# AM13E23219 register map
Vendor: Texas Instruments; File version: 1.0
CPU: CM33 r0p1, little endian, MPU, FPU, VTOR, 4 interrupt priority bits
Registers are 32-bit, read-write, reset 0x0 unless marked. A register's access mark holds for its fields unless they carry their own. Offsets are from the block's base; [hi:lo] are bit positions; lines under a group give offsets from that group; {n}, {i} and the like mark numbered series; 'fields as' and 'values as' point back to an identical list.

## MCPWM0 — MCPWM module
Base 0x40010000
Same registers: MCPWM1 0x40011000, MCPWM2 0x40012000
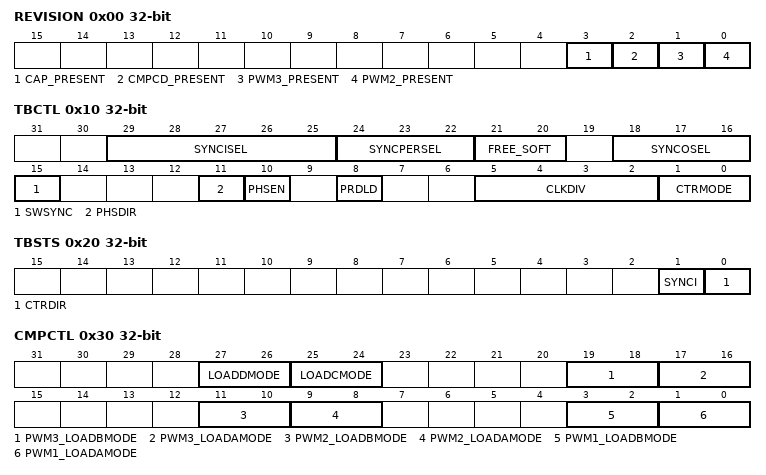
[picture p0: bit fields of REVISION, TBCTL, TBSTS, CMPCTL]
0x00 REVISION ro — IP revision id register
  [3] CAP_PRESENT — Capture mode Present
  [2] CMPCD_PRESENT — Compare C and D Present
  [1] PWM3_PRESENT
  [0] PWM2_PRESENT
0x10 TBCTL — Time base control register
  [29:25] SYNCISEL — Sync Input Select
  [24:22] SYNCPERSEL — Sync peripheral Select
  [21:20] FREE_SOFT — Emulation Mode Bits
  [18:16] SYNCOSEL — Sync Output Select
  [15] SWSYNC — Software Force Sync Pulse
  [11] PHSDIR — Phase Direction Bit
  [10] PHSEN — Phase Load Enable
  [8] PRDLD — Shadow to active load of TBPRD
  [5:2] CLKDIV — Time Base Clock Pre-scaler
  [1:0] CTRMODE — Counter Mode
0x14 TBPRD — Time base period register
  [15:0] TBPRD
0x18 TBPRDS — Time base period shadow register
  [15:0] TBPRDS
0x1C TBPHS — Time base phase offset register
  [15:0] TBPHS — Phase Offset Register
0x20 TBSTS ro — Time base status register
  [1] SYNCI — External Input Sync Status
  [0] CTRDIR — Counter Direction Status
0x24 TBSTSCLR — Time base status clear register
  [1] SYNCI — External Input Sync Status clear
0x28 TBCTR — Time base counter register
  [15:0] TBCTR — Counter Value
0x30 CMPCTL — Counter compare control register
  [27:26] LOADDMODE — Shadow to active load of CMPD
  [25:24] LOADCMODE — Shadow to active load of CMPC
  [19:18] PWM3_LOADBMODE — Shadow to active load of PWM3_CMPB
  [17:16] PWM3_LOADAMODE — Shadow to active load of PWM3_CMPA
  [11:10] PWM2_LOADBMODE — Shadow to active load of PWM2_CMPB
  [9:8] PWM2_LOADAMODE — Shadow to active load of PWM2_CMPA
  [3:2] PWM1_LOADBMODE — Shadow to active load of PWM1_CMPB
  [1:0] PWM1_LOADAMODE — Shadow to active load of PWM1_CMPA
0x40 CMPC — Counter compare C register
  [15:0] CMPC — Compare C register
0x44 CMPD — Counter compare D register
  [15:0] CMPD — Compare D register
0x48 CMPCS — Counter compare C shadow register
  [15:0] CMPCS — Compare C shadow register
0x4C CMPDS — Counter compare D shadow register
  [15:0] CMPDS — Compare D shadow register
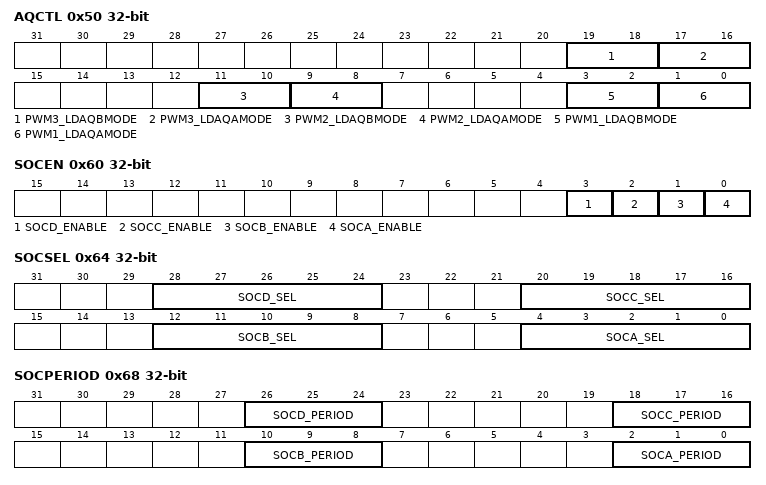
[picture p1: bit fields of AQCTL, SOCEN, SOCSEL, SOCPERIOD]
0x50 AQCTL — Action qualifier control register
  [19:18] PWM3_LDAQBMODE — Shadow to active load of PWM3_AQCTLB
  [17:16] PWM3_LDAQAMODE — Shadow to active load of PWM3_AQCTLA
  [11:10] PWM2_LDAQBMODE — Shadow to active load of PWM2_AQCTLB
  [9:8] PWM2_LDAQAMODE — Shadow to active load of PWM2_AQCTLA
  [3:2] PWM1_LDAQBMODE — Shadow to active load of PWM1_AQCTLB
  [1:0] PWM1_LDAQAMODE — Shadow to active load of PWM1_AQCTLA
0x60 SOCEN — Start of conversion enable
  [3] SOCD_ENABLE — Start of conversion (SOC) D enable
  [2] SOCC_ENABLE — Start of conversion (SOC) C enable
  [1] SOCB_ENABLE — Start of conversion (SOC) B enable
  [0] SOCA_ENABLE — Start of conversion (SOC) A enable
0x64 SOCSEL — Start of conversion selection
  [28:24] SOCD_SEL — Start of conversion (SOC) D select
  [20:16] SOCC_SEL — Start of conversion (SOC) C select
  [12:8] SOCB_SEL — Start of conversion (SOC) B select
  [4:0] SOCA_SEL — Start of conversion (SOC) A select
0x68 SOCPERIOD — Start of conversion period
  [26:24] SOCD_PERIOD — Start of conversion (SOC) D PERIOD
  [18:16] SOCC_PERIOD — Start of conversion (SOC) C PERIOD
  [10:8] SOCB_PERIOD — Start of conversion (SOC) B PERIOD
  [2:0] SOCA_PERIOD — Start of conversion (SOC) A PERIOD
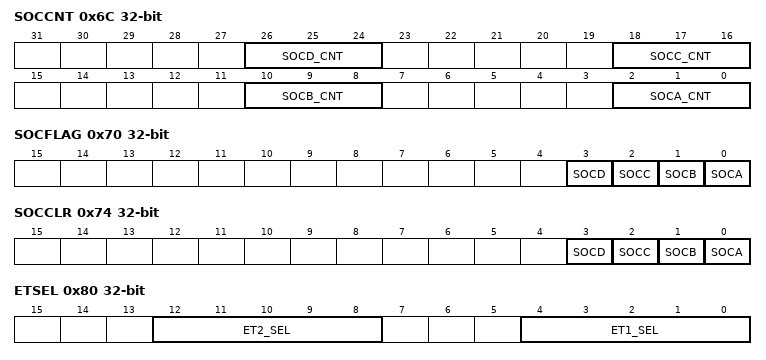
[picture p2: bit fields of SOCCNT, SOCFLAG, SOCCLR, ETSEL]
0x6C SOCCNT ro — Start of conversion count
  [26:24] SOCD_CNT — Start of conversion (SOC) D COUNT
  [18:16] SOCC_CNT — Start of conversion (SOC) C COUNT
  [10:8] SOCB_CNT — Start of conversion (SOC) B COUNT
  [2:0] SOCA_CNT — Start of conversion (SOC) A COUNT
0x70 SOCFLAG ro — Start of conversion flag
  [3] SOCD — SOCD Flag
  [2] SOCC — SOCC Flag
  [1] SOCB — SOCB Flag
  [0] SOCA — SOCA Flag
0x74 SOCCLR — Start of conversion clear
  [3] SOCD — SOCD Clear
  [2] SOCC — SOCC Clear
  [1] SOCB — SOCB Clear
  [0] SOCA — SOCA Clear
0x80 ETSEL — Event trigger selection
  [12:8] ET2_SEL — Event trigger2 selection
  [4:0] ET1_SEL — Event trigger1 selection
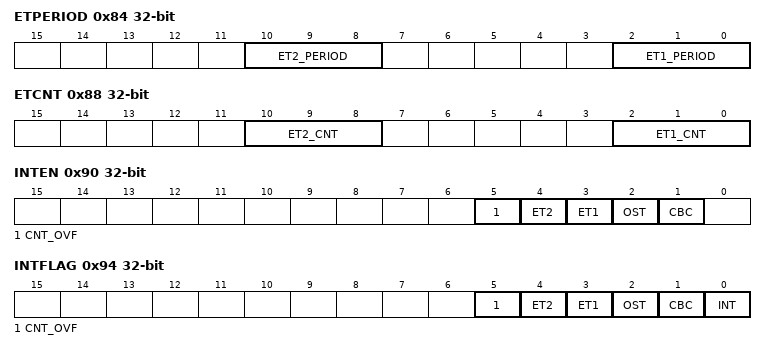
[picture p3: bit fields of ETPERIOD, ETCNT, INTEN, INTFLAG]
0x84 ETPERIOD — Event trigger period
  [10:8] ET2_PERIOD — Event trigger2 PERIOD
  [2:0] ET1_PERIOD — Event trigger1 PERIOD
0x88 ETCNT ro — Event trigger count
  [10:8] ET2_CNT — Event trigger2 COUNT
  [2:0] ET1_CNT — Event trigger1 COUNT
0x90 INTEN — Interrupt enable
  [5] CNT_OVF — Counter overflow interrupt
  [4] ET2 — Enable ET2 interrupt
  [3] ET1 — Enable ET1 interrupt
  [2] OST — Enable OST interrupt
  [1] CBC — Enable CBC interrupt
0x94 INTFLAG ro — Interrupt flag
  [5] CNT_OVF — Counter overflow flag
  [4] ET2 — ET2 interrupt flag
  [3] ET1 — ET1 interrupt flag
  [2] OST — OST interrupt flag
  [1] CBC — CBC interrupt flag
  [0] INT — Global Flag
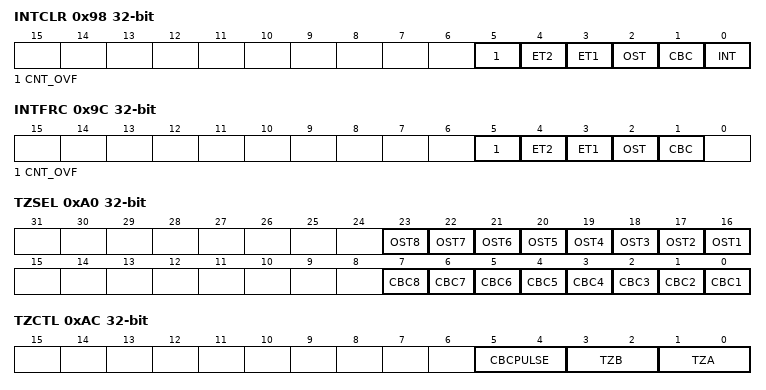
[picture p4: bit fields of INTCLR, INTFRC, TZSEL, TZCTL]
0x98 INTCLR — Interrupt clear
  [5] CNT_OVF — Counter overflow flag
  [4] ET2 — Clear ET2 interrupt flag
  [3] ET1 — Clear ET1 interrupt flag
  [2] OST — Clear OST interrupt flag
  [1] CBC — Clear CBC interrupt flag
  [0] INT — Clear Global Flag
0x9C INTFRC — Interrupt force
  [5] CNT_OVF — Counter overflow flag
  [4] ET2 — Force ET2 interrupt flag
  [3] ET1 — Force ET1 interrupt flag
  [2] OST — Force OST interrupt flag
  [1] CBC — Force CBC interrupt flag
0xA0 TZSEL — Trip Zone selection
  [n+15] OST{n} (n=1..8) — OST TZ{n} select
  [n-1] CBC{n} (n=1..8) — CBC TZ{n} select
0xAC TZCTL — Trip Zone control
  [5:4] CBCPULSE — Clear Pulse for CBC Trip Latch
  [3:2] TZB — TZ1 to TZ8 Trip Action on PWMB
  [1:0] TZA — TZ1 to TZ8 Trip Action on PWMA
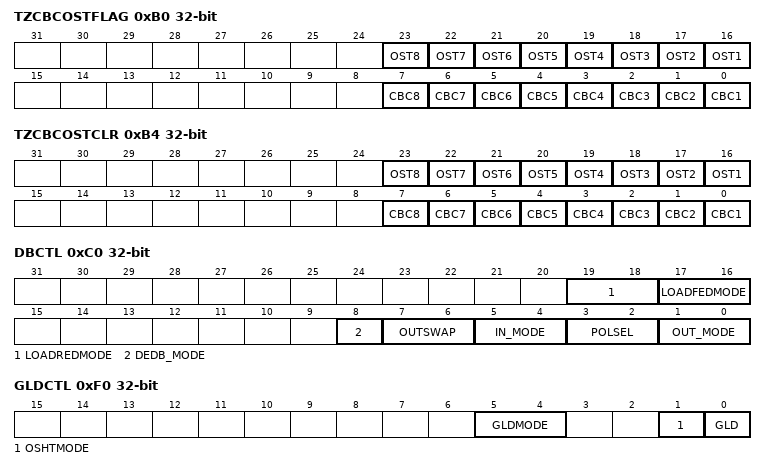
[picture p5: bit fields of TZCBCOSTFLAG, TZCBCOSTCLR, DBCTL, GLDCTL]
0xB0 TZCBCOSTFLAG ro — Trip zone CBCOST flag
  [n+15] OST{n} (n=1..8) — OST TZ{n} Flag
  [7] CBC8 — OST TZ8 Flag
  [n-1] CBC{n} (n=1..7) — CBC TZ{n} Flag
0xB4 TZCBCOSTCLR — Trip zone CBCOST flag clear
  [n+15] OST{n} (n=1..8) — OST TZ{n} Clear
  [7] CBC8 — OST TZ8 Clear
  [n-1] CBC{n} (n=1..7) — CBC TZ{n} Clear
0xC0 DBCTL — Dead band control register
  [19:18] LOADREDMODE — Shadow to active load of DBRED
  [17:16] LOADFEDMODE — Shadow to active load of DBFED
  [8] DEDB_MODE — Dead Band Dual-Edge B Mode Control
  [7:6] OUTSWAP — Dead Band Output Swap Control
  [5:4] IN_MODE — Dead Band Input Select Mode Control
  [3:2] POLSEL — Polarity Select Control
  [1:0] OUT_MODE — Dead Band Output Mode Control
0xD0 DBFED — Dead band fall edge delay
  [13:0] DBFED — Falling edge delay value
0xD4 DBRED — Dead band rise edge delay
  [13:0] DBRED — Rising edge delay value
0xD8 DBFEDS — Dead band fall edge delay shadow register
  [13:0] DBFEDS — Falling edge delay shadow register
0xDC DBREDS — Dead band rise edge delay shadow register
  [13:0] DBREDS — Rising edge delay shadow register
0xF0 GLDCTL — Global load control register
  [5:4] GLDMODE — Select global load event
  [1] OSHTMODE — Global load one-shot enable
  [0] GLD — Global load enable
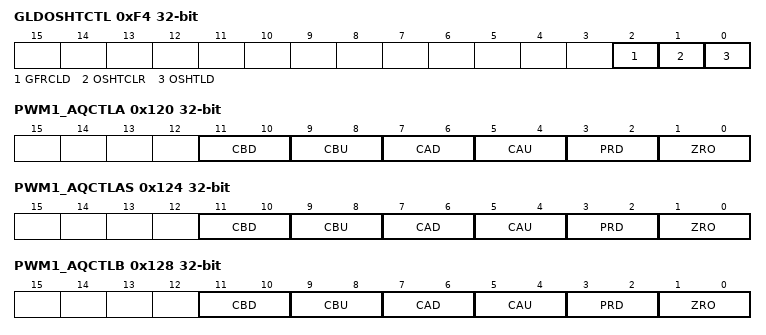
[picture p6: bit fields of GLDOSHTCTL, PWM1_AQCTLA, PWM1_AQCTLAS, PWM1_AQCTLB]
0xF4 GLDOSHTCTL — Global load one shot control register
  [2] GFRCLD — Force load event in one shot mode
  [1] OSHTCLR — Enable Reload Event in One Shot Mode
  [0] OSHTLD — Enable Reload Event in One Shot Mode
0xF8 GLDOSHTSTS ro — Global load one shot status register
  [0] OSHTLATCH — One shot latch output
0x100 PWM1_CMPA — PWM1 counter compare A register
  [15:0] PWM1_CMPA — PWM1 Compare A register
0x104 PWM1_CMPAS — PWM1 counter compare A shadow register
  [15:0] PWM1_CMPAS — PWM1 Compare A shadow register
0x108 PWM1_CMPB — PWM1 counter compare B register
  [15:0] PWM1_CMPB — PWM1 Compare B register
0x10C PWM1_CMPBS — PWM1 counter compare B shadow register
  [15:0] PWM1_CMPBS — PWM1 Compare B shadow register
0x120 PWM1_AQCTLA — PWM1 action qualifier A register
  [11:10] CBD — Action When TBCTR = PWM1_CMPB on Down Count
  [9:8] CBU — Action When TBCTR = PWM1_CMPB on Up Count
  [7:6] CAD — Action When TBCTR = PWM1_CMPA on Down Count
  [5:4] CAU — Action When TBCTR = PWM1_CMPA on Up Count
  [3:2] PRD — Action When TBCTR = TBPRD
  [1:0] ZRO — Action When TBCTR = 0
0x124 PWM1_AQCTLAS — PWM1 action qualifier A shadow register
  fields as PWM1_AQCTLA
0x128 PWM1_AQCTLB — PWM1 action qualifier B register
  fields as PWM1_AQCTLA
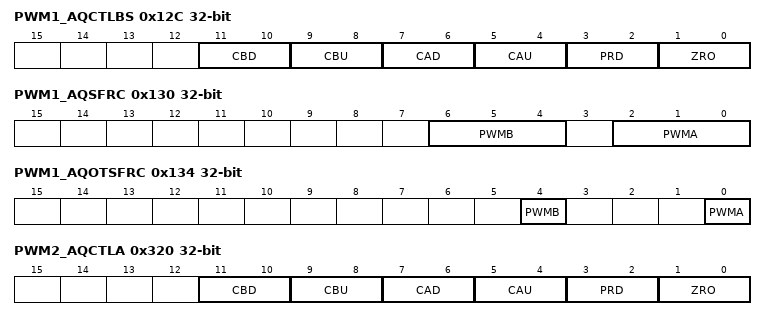
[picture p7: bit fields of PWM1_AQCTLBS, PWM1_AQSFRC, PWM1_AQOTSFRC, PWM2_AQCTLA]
0x12C PWM1_AQCTLBS — PWM1 action qualifier B shadow register
  fields as PWM1_AQCTLA
0x130 PWM1_AQSFRC — PWM1 action qualifier software force
  [6:4] PWMB — Action qualifier software force on PWMB
  [2:0] PWMA — Action qualifier software force on PWMA
0x134 PWM1_AQOTSFRC — PWM1 action qualifier one time software force
  [4] PWMB — Action qualifier software force on PWMB
  [0] PWMA — Action qualifier one time software force on PWMA
0x300 PWM2_CMPA — PWM2 counter compare A register
  [15:0] PWM2_CMPA — PWM2 Compare A register
0x304 PWM2_CMPAS — PWM2 counter compare A shadow register
  [15:0] PWM2_CMPAS — PWM2 Compare A shadow register
0x308 PWM2_CMPB — PWM2 counter compare B register
  [15:0] PWM2_CMPB — PWM2 Compare B register
0x30C PWM2_CMPBS — PWM2 counter compare B shadow register
  [15:0] PWM2_CMPBS — PWM2 Compare B shadow register
0x320 PWM2_AQCTLA — PWM2 action qualifier A register
  [11:10] CBD — Action When TBCTR = PWM2_CMPB on Down Count
  [9:8] CBU — Action When TBCTR = PWM2_CMPB on Up Count
  [7:6] CAD — Action When TBCTR = PWM2_CMPA on Down Count
  [5:4] CAU — Action When TBCTR = PWM2_CMPA on Up Count
  [3:2] PRD — Action When TBCTR = TBPRD
  [1:0] ZRO — Action When TBCTR = 0
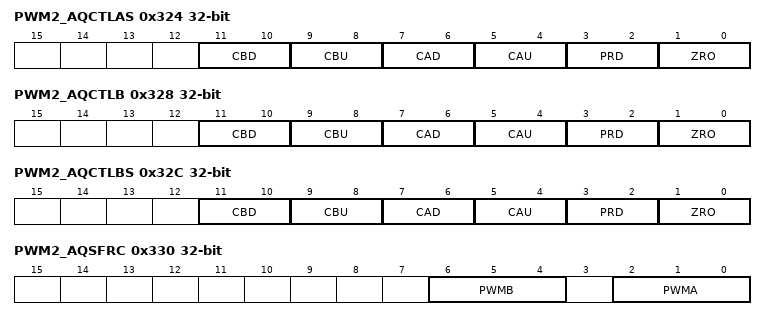
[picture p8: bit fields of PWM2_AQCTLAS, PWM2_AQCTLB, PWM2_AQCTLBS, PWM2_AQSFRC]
0x324 PWM2_AQCTLAS — PWM2 action qualifier A shadow register
  fields as PWM2_AQCTLA
0x328 PWM2_AQCTLB — PWM2 action qualifier B register
  fields as PWM2_AQCTLA
0x32C PWM2_AQCTLBS — PWM2 action qualifier B shadow register
  fields as PWM2_AQCTLA
0x330 PWM2_AQSFRC — PWM2 action qualifier software force
  fields as PWM1_AQSFRC
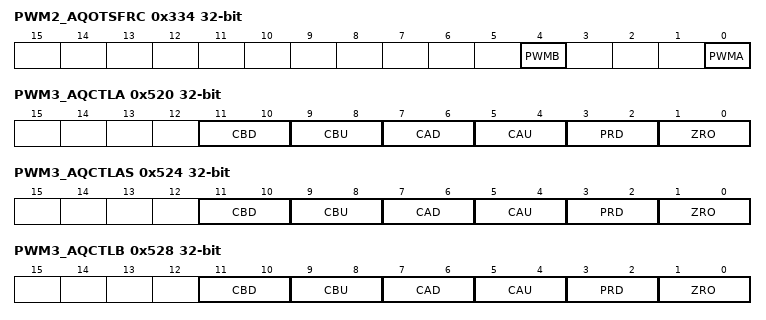
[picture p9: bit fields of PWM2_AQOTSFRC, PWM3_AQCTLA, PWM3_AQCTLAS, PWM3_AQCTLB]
0x334 PWM2_AQOTSFRC — PWM2 action qualifier one time software force
  fields as PWM1_AQOTSFRC
0x500 PWM3_CMPA — PWM3 counter compare A register
  [15:0] PWM3_CMPA — PWM3 Compare A register
0x504 PWM3_CMPAS — PWM3 counter compare A shadow register
  [15:0] PWM3_CMPAS — PWM3 Compare A shadow register
0x508 PWM3_CMPB — PWM3 counter compare B register
  [15:0] PWM3_CMPB — PWM3 Compare B register
0x50C PWM3_CMPBS — PWM3 counter compare B shadow register
  [15:0] PWM3_CMPBS — PWM3 Compare B shadow register
0x520 PWM3_AQCTLA — PWM3 action qualifier A register
  [11:10] CBD — Action When TBCTR = PWM3_CMPB on Down Count
  [9:8] CBU — Action When TBCTR = PWM3_CMPB on Up Count
  [7:6] CAD — Action When TBCTR = PWM3_CMPA on Down Count
  [5:4] CAU — Action When TBCTR = PWM3_CMPA on Up Count
  [3:2] PRD — Action When TBCTR = TBPRD
  [1:0] ZRO — Action When TBCTR = 0
0x524 PWM3_AQCTLAS — PWM3 action qualifier A shadow register
  fields as PWM3_AQCTLA
0x528 PWM3_AQCTLB — PWM3 action qualifier B register
  fields as PWM3_AQCTLA
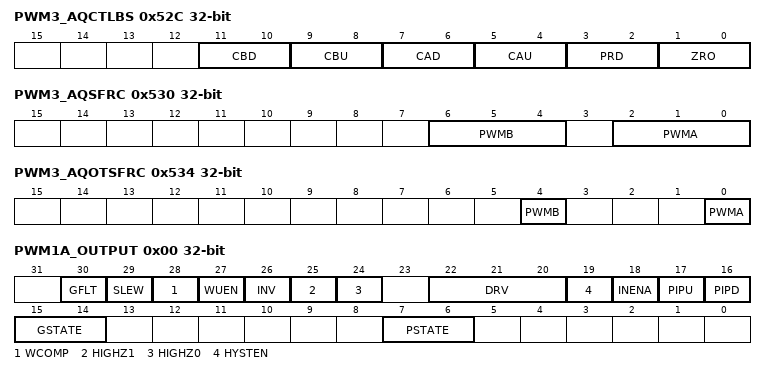
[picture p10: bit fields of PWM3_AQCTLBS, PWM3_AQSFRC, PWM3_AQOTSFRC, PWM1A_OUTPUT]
0x52C PWM3_AQCTLBS — PWM3 action qualifier B shadow register
  fields as PWM3_AQCTLA
0x530 PWM3_AQSFRC — PWM3 action qualifier software force
  fields as PWM1_AQSFRC
0x534 PWM3_AQOTSFRC — PWM3 action qualifier one time software force
  fields as PWM1_AQOTSFRC
0x604 PINCM group
  0x00 PWM1A_OUTPUT — PWM1A output interface (fout=data, foe=output enable)
    [30] GFLT — Glitch Filter Enable
      0=DISABLE (No internal glitch filter); 1=ENABLE (Use internal glitch filter)
    [29] SLEW — Reserved Slew Rate Control
      0=DISABLE (No Slew Rate Control); 1=ENABLE (Use Slew Rate Control)
    [28] WCOMP — Wake up compare value
      0=MATCH_ZERO (Match 0 will wake); 1=MATCH_ONE (Match 1 will wake)
    [27] WUEN — Wake up enable
      0=NO_WAKEUP (Wake up not enabled); 1=WAKEUP (Wake up enabled)
    [26] INV — Invert digital input/output relative to peripheral/GPIO
      0=NO_CHNG (Input and output are non-inverted); 1=CHNG (Input and output are inverted)
    [25] HIGHZ1 — High-Z instead of high output
      0=DRV_HIGH (Pin can be driven high); 1=DRV_HIZ (Pin is tri-stated instead of driven high)
    [24] HIGHZ0 — High-Z instead of low output
      0=DRV_LOW (Pin can be driven low); 1=DRV_HIZ (Pin is tri-stated instead of driven low)
    [22:20] DRV — Drive strength options
      0=STRENGTH_0 (Lowest drive strength); {v}=STRENGTH_{v} (Drive strength {v+1}/8) (v=1..6); 7=STRENGTH_7 (Highest drive strength)
    [19] HYSTEN — Hysteresis enable
      0=DIS_HYST (No hysteresis); 1=EN_HYST (Hysteresis on)
    [18] INENA — Input enable
      0=INP_DISABLE (Inputs 0 to connected core); 1=INP_ENABLE (Inputs IO pad value to connected core)
    [17] PIPU — Pull up enable
      0=NO_PULL_UP; 1=PULL_UP
    [16] PIPD — Pull down enable
      0=NO_PULL_DOWN; 1=PULL_DOWN
    [15:14] GSTATE — GPIO Channel State
      0=UNASSIGNED (G-Channel is in Unassigned State); 1=HANDOVER (G-Channel is in Handover State); 2=CONC_NOT_LOCKED (G-Channel is in Connected State and not Locked (That is F field is allowed to change without going back through Unassigned state)); 3=CONC_LOCKED (G-Channel is in Connected State and Locked (That is F field is not allowed to change to a different non-Zero value until both G and P channels go to Unassigned))
    [7:6] PSTATE — Peripheral-Analog Channel State
      0=UNASSIGNED (P-Channel is in Unassigned State); 1=HANDOVER (P-Channel is in Handover State); 2=CONC_NOT_LOCKED (P-Channel is in Connected State and not Locked (That is F field is allowed to change without going back through Unassigned state)); 3=CONC_LOCKED (P-Channel is in Connected State and Locked (That is F field is not allowed to change to a different non-Zero value until both G and P channels go to Unassigned))
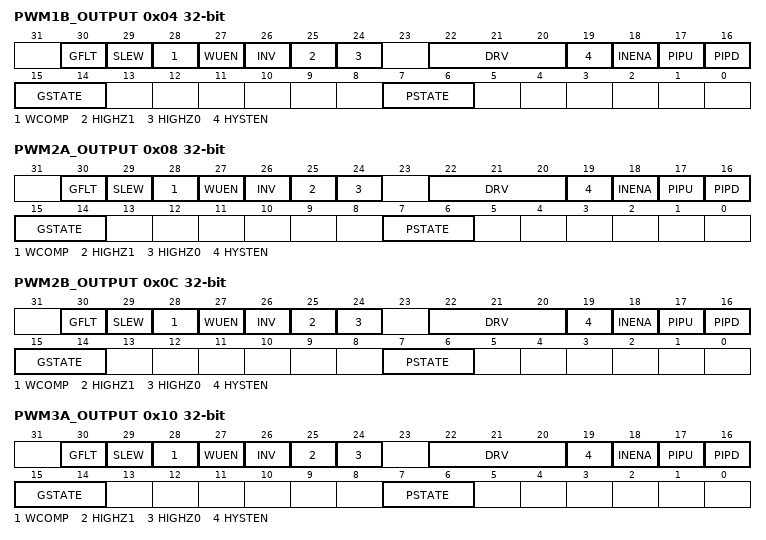
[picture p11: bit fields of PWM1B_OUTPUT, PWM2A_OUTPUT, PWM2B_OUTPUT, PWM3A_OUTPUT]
  0x04 PWM1B_OUTPUT — PWM1B output interface (fout=data, foe=output enable)
    fields as PINCM.PWM1A_OUTPUT
  0x08 PWM2A_OUTPUT — PWM2A output interface (fout=data, foe=output enable)
    fields as PINCM.PWM1A_OUTPUT
  0x0C PWM2B_OUTPUT — PWM2B output interface (fout=data, foe=output enable)
    fields as PINCM.PWM1A_OUTPUT
  0x10 PWM3A_OUTPUT — PWM3A output interface (fout=data, foe=output enable)
    fields as PINCM.PWM1A_OUTPUT
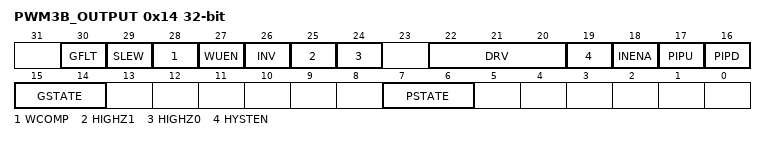
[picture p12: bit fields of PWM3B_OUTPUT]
  0x14 PWM3B_OUTPUT — PWM3B output interface (fout=data, foe=output enable)
    fields as PINCM.PWM1A_OUTPUT
0x804 FUPDATE group
  0x00 PWM1A_OUTPUT — FUPDATE version of PWM1A_OUTPUT
    [27:2] IOADDR — IO Address. This is the address that corresponds to the SOC address[27:2] of the module IP instance specific IO signal in the "Full Write" subregion of the pinmux subregion.
    [1] LOCK — Sets lock bit
      0=NOEFFECT (Writing this value has no effect); 1=LOCK (Set channel lock bit)
    [0] GSEL — GPIO channel Select 0: Select the P-Channel for the F update 1: Select the G-Channel for the F update
      0=PCHAN (Select the P-Channel for the F update); 1=GCHAN (Select the G-Channel for the F update)
  0x04 PWM1B_OUTPUT — FUPDATE version of PWM1B_OUTPUT
    fields as FUPDATE.PWM1A_OUTPUT
  0x08 PWM2A_OUTPUT — FUPDATE version of PWM2A_OUTPUT
    fields as FUPDATE.PWM1A_OUTPUT
  0x0C PWM2B_OUTPUT — FUPDATE version of PWM2B_OUTPUT
    fields as FUPDATE.PWM1A_OUTPUT
  0x10 PWM3A_OUTPUT — FUPDATE version of PWM3A_OUTPUT
    fields as FUPDATE.PWM1A_OUTPUT
  0x14 PWM3B_OUTPUT — FUPDATE version of PWM3B_OUTPUT
    fields as FUPDATE.PWM1A_OUTPUT
